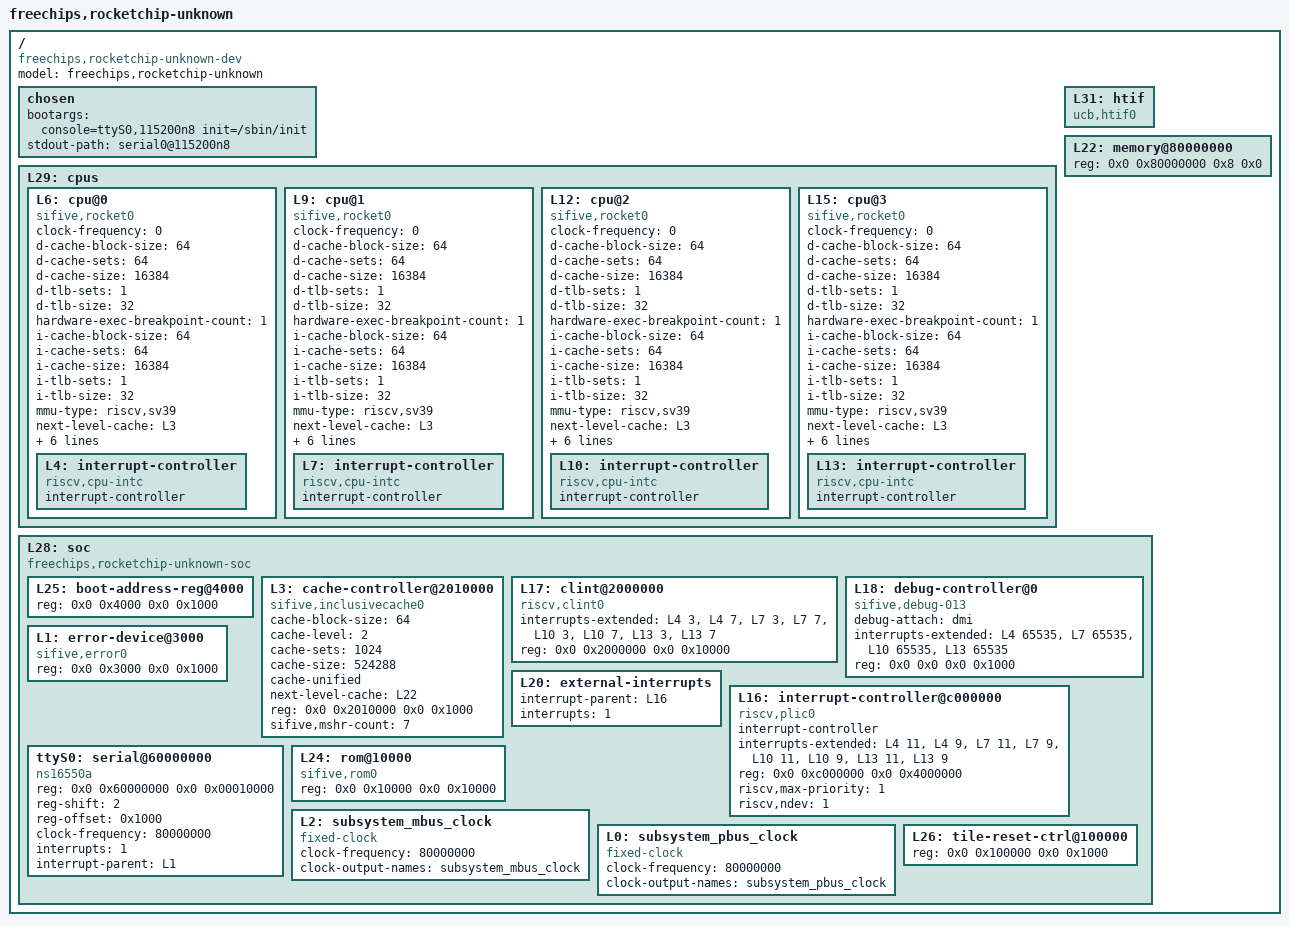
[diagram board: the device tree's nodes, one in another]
/dts-v1/;

/ {
	#address-cells = <2>;
	#size-cells = <2>;
	compatible = "freechips,rocketchip-unknown-dev";
	model = "freechips,rocketchip-unknown";
	
	chosen {
		bootargs = "console=ttyS0,115200n8 init=/sbin/init";
		stdout-path = "serial0@115200n8";
	};

	L29: cpus {
		#address-cells = <1>;
		#size-cells = <0>;
		L6: cpu@0 {
			clock-frequency = <0>;
			compatible = "sifive,rocket0", "riscv";
			d-cache-block-size = <64>;
			d-cache-sets = <64>;
			d-cache-size = <16384>;
			d-tlb-sets = <1>;
			d-tlb-size = <32>;
			device_type = "cpu";
			hardware-exec-breakpoint-count = <1>;
			i-cache-block-size = <64>;
			i-cache-sets = <64>;
			i-cache-size = <16384>;
			i-tlb-sets = <1>;
			i-tlb-size = <32>;
			mmu-type = "riscv,sv39";
			next-level-cache = <&L3>;
			reg = <0x0>;
			riscv,isa = "rv64imafdc";
			riscv,pmpgranularity = <4>;
			riscv,pmpregions = <8>;
			status = "okay";
			timebase-frequency = <1000000>;
			tlb-split;
			L4: interrupt-controller {
				#interrupt-cells = <1>;
				compatible = "riscv,cpu-intc";
				interrupt-controller;
			};
		};
		L9: cpu@1 {
			clock-frequency = <0>;
			compatible = "sifive,rocket0", "riscv";
			d-cache-block-size = <64>;
			d-cache-sets = <64>;
			d-cache-size = <16384>;
			d-tlb-sets = <1>;
			d-tlb-size = <32>;
			device_type = "cpu";
			hardware-exec-breakpoint-count = <1>;
			i-cache-block-size = <64>;
			i-cache-sets = <64>;
			i-cache-size = <16384>;
			i-tlb-sets = <1>;
			i-tlb-size = <32>;
			mmu-type = "riscv,sv39";
			next-level-cache = <&L3>;
			reg = <0x1>;
			riscv,isa = "rv64imafdc";
			riscv,pmpgranularity = <4>;
			riscv,pmpregions = <8>;
			status = "okay";
			timebase-frequency = <1000000>;
			tlb-split;
			L7: interrupt-controller {
				#interrupt-cells = <1>;
				compatible = "riscv,cpu-intc";
				interrupt-controller;
			};
		};
		L12: cpu@2 {
			clock-frequency = <0>;
			compatible = "sifive,rocket0", "riscv";
			d-cache-block-size = <64>;
			d-cache-sets = <64>;
			d-cache-size = <16384>;
			d-tlb-sets = <1>;
			d-tlb-size = <32>;
			device_type = "cpu";
			hardware-exec-breakpoint-count = <1>;
			i-cache-block-size = <64>;
			i-cache-sets = <64>;
			i-cache-size = <16384>;
			i-tlb-sets = <1>;
			i-tlb-size = <32>;
			mmu-type = "riscv,sv39";
			next-level-cache = <&L3>;
			reg = <0x2>;
			riscv,isa = "rv64imafdc";
			riscv,pmpgranularity = <4>;
			riscv,pmpregions = <8>;
			status = "okay";
			timebase-frequency = <1000000>;
			tlb-split;
			L10: interrupt-controller {
				#interrupt-cells = <1>;
				compatible = "riscv,cpu-intc";
				interrupt-controller;
			};
		};
		L15: cpu@3 {
			clock-frequency = <0>;
			compatible = "sifive,rocket0", "riscv";
			d-cache-block-size = <64>;
			d-cache-sets = <64>;
			d-cache-size = <16384>;
			d-tlb-sets = <1>;
			d-tlb-size = <32>;
			device_type = "cpu";
			hardware-exec-breakpoint-count = <1>;
			i-cache-block-size = <64>;
			i-cache-sets = <64>;
			i-cache-size = <16384>;
			i-tlb-sets = <1>;
			i-tlb-size = <32>;
			mmu-type = "riscv,sv39";
			next-level-cache = <&L3>;
			reg = <0x3>;
			riscv,isa = "rv64imafdc";
			riscv,pmpgranularity = <4>;
			riscv,pmpregions = <8>;
			status = "okay";
			timebase-frequency = <1000000>;
			tlb-split;
			L13: interrupt-controller {
				#interrupt-cells = <1>;
				compatible = "riscv,cpu-intc";
				interrupt-controller;
			};
		};
	};
	L31: htif {
		compatible = "ucb,htif0";
	};
	L22: memory@80000000 {
		device_type = "memory";
		reg = <0x0 0x80000000 0x8 0x0>;
	};
	L28: soc {
		#address-cells = <2>;
		#size-cells = <2>;
		compatible = "freechips,rocketchip-unknown-soc", "simple-bus";
		ranges;
		L25: boot-address-reg@4000 {
			reg = <0x0 0x4000 0x0 0x1000>;
			reg-names = "control";
		};
		L3: cache-controller@2010000 {
			cache-block-size = <64>;
			cache-level = <2>;
			cache-sets = <1024>;
			cache-size = <524288>;
			cache-unified;
			compatible = "sifive,inclusivecache0", "cache";
			next-level-cache = <&L22>;
			reg = <0x0 0x2010000 0x0 0x1000>;
			reg-names = "control";
			sifive,mshr-count = <7>;
		};
		L17: clint@2000000 {
			compatible = "riscv,clint0";
			interrupts-extended = <&L4 3 &L4 7 &L7 3 &L7 7 &L10 3 &L10 7 &L13 3 &L13 7>;
			reg = <0x0 0x2000000 0x0 0x10000>;
			reg-names = "control";
		};
		L18: debug-controller@0 {
			compatible = "sifive,debug-013", "riscv,debug-013";
			debug-attach = "dmi";
			interrupts-extended = <&L4 65535 &L7 65535 &L10 65535 &L13 65535>;
			reg = <0x0 0x0 0x0 0x1000>;
			reg-names = "control";
		};
		L1: error-device@3000 {
			compatible = "sifive,error0";
			reg = <0x0 0x3000 0x0 0x1000>;
		};
		L20: external-interrupts {
			interrupt-parent = <&L16>;
			interrupts = <1>;
		};
		L16: interrupt-controller@c000000 {
			#interrupt-cells = <1>;
			compatible = "riscv,plic0";
			interrupt-controller;
			interrupts-extended = <&L4 11 &L4 9 &L7 11 &L7 9 &L10 11 &L10 9 &L13 11 &L13 9>;
			reg = <0x0 0xc000000 0x0 0x4000000>;
			reg-names = "control";
			riscv,max-priority = <1>;
			riscv,ndev = <1>;
		};
		ttyS0: serial@60000000 {
			compatible = "ns16550a";
			reg = <0x0 0x60000000 0x0 0x00010000>;
			
			reg-shift = <2>;
			reg-offset = <0x1000>;

			device_type = "serial";
			clock-frequency = <80000000>;
 			
 			interrupts = <1>;
			interrupt-parent = <&L1>;
		};
		L24: rom@10000 {
			compatible = "sifive,rom0";
			reg = <0x0 0x10000 0x0 0x10000>;
			reg-names = "mem";
		};
		L2: subsystem_mbus_clock {
			#clock-cells = <0>;
			clock-frequency = <80000000>;
			clock-output-names = "subsystem_mbus_clock";
			compatible = "fixed-clock";
		};
		L0: subsystem_pbus_clock {
			#clock-cells = <0>;
			clock-frequency = <80000000>;
			clock-output-names = "subsystem_pbus_clock";
			compatible = "fixed-clock";
		};
		L26: tile-reset-ctrl@100000 {
			reg = <0x0 0x100000 0x0 0x1000>;
			reg-names = "control";
		};
	};
};
